# MIMXRT1062 register map
Vendor: nxp.com; File version: 1.0
CPU: CM7 r0p1, little endian, MPU, FPU, VTOR, 4 interrupt priority bits
Registers are 32-bit, read-write, reset 0x0 unless marked. A register's access mark holds for its fields unless they carry their own. Offsets are from the block's base; [hi:lo] are bit positions; {n}, {i} and the like mark numbered series; 'fields as' and 'values as' point back to an identical list.

## IOMUXC (part 3 of 4)
Base 0x401F8000; register names take the prefix IOMUXC_
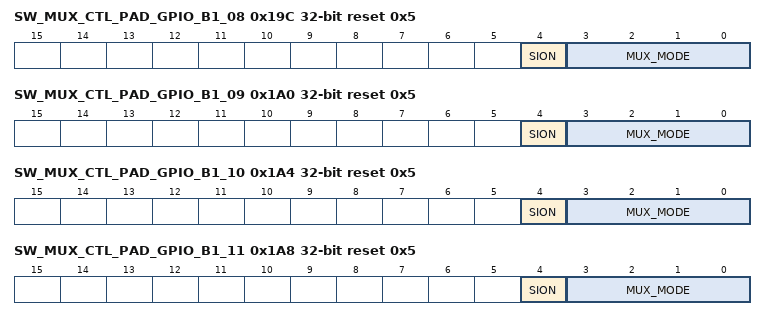
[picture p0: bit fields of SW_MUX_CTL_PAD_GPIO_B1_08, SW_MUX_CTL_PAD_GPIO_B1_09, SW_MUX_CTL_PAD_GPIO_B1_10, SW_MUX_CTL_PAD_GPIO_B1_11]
0x19C SW_MUX_CTL_PAD_GPIO_B1_08 reset 0x5 — SW_MUX_CTL_PAD_GPIO_B1_08 SW MUX Control Register
  [4] SION — Software Input On Field.
    0=DISABLED (Input Path is determined by functionality); 1=ENABLED (Force input path of pad GPIO_B1_08)
  [3:0] MUX_MODE — MUX Mode Select Field.
    0=ALT0 (Select mux mode: ALT0 mux port: LCD_DATA20 of instance: lcdif); 1=ALT1 (Select mux mode: ALT1 mux port: QTIMER1_TIMER3 of instance: qtimer1); 2=ALT2 (Select mux mode: ALT2 mux port: CSI_DATA11 of instance: csi); 3=ALT3 (Select mux mode: ALT3 mux port: ENET_TX_DATA01 of instance: enet); 4=ALT4 (Select mux mode: ALT4 mux port: FLEXIO2_FLEXIO24 of instance: flexio2); 5=ALT5 (Select mux mode: ALT5 mux port: GPIO2_IO24 of instance: gpio2); 6=ALT6 (Select mux mode: ALT6 mux port: FLEXCAN2_TX of instance: flexcan2); 8=ALT8 (Select mux mode: ALT8 mux port: GPT1_COMPARE2 of instance: gpt1); 9=ALT9 (Select mux mode: ALT9 mux port: FLEXIO3_FLEXIO24 of instance: flexio3)
0x1A0 SW_MUX_CTL_PAD_GPIO_B1_09 reset 0x5 — SW_MUX_CTL_PAD_GPIO_B1_09 SW MUX Control Register
  [4] SION — Software Input On Field.
    0=DISABLED (Input Path is determined by functionality); 1=ENABLED (Force input path of pad GPIO_B1_09)
  [3:0] MUX_MODE — MUX Mode Select Field.
    0=ALT0 (Select mux mode: ALT0 mux port: LCD_DATA21 of instance: lcdif); 1=ALT1 (Select mux mode: ALT1 mux port: QTIMER2_TIMER3 of instance: qtimer2); 2=ALT2 (Select mux mode: ALT2 mux port: CSI_DATA10 of instance: csi); 3=ALT3 (Select mux mode: ALT3 mux port: ENET_TX_EN of instance: enet); 4=ALT4 (Select mux mode: ALT4 mux port: FLEXIO2_FLEXIO25 of instance: flexio2); 5=ALT5 (Select mux mode: ALT5 mux port: GPIO2_IO25 of instance: gpio2); 6=ALT6 (Select mux mode: ALT6 mux port: FLEXCAN2_RX of instance: flexcan2); 8=ALT8 (Select mux mode: ALT8 mux port: GPT1_COMPARE3 of instance: gpt1); 9=ALT9 (Select mux mode: ALT9 mux port: FLEXIO3_FLEXIO25 of instance: flexio3)
0x1A4 SW_MUX_CTL_PAD_GPIO_B1_10 reset 0x5 — SW_MUX_CTL_PAD_GPIO_B1_10 SW MUX Control Register
  [4] SION — Software Input On Field.
    0=DISABLED (Input Path is determined by functionality); 1=ENABLED (Force input path of pad GPIO_B1_10)
  [3:0] MUX_MODE — MUX Mode Select Field.
    0=ALT0 (Select mux mode: ALT0 mux port: LCD_DATA22 of instance: lcdif); 1=ALT1 (Select mux mode: ALT1 mux port: QTIMER3_TIMER3 of instance: qtimer3); 2=ALT2 (Select mux mode: ALT2 mux port: CSI_DATA00 of instance: csi); 3=ALT3 (Select mux mode: ALT3 mux port: ENET_TX_CLK of instance: enet); 4=ALT4 (Select mux mode: ALT4 mux port: FLEXIO2_FLEXIO26 of instance: flexio2); 5=ALT5 (Select mux mode: ALT5 mux port: GPIO2_IO26 of instance: gpio2); 6=ALT6 (Select mux mode: ALT6 mux port: ENET_REF_CLK of instance: enet); 9=ALT9 (Select mux mode: ALT9 mux port: FLEXIO3_FLEXIO26 of instance: flexio3)
0x1A8 SW_MUX_CTL_PAD_GPIO_B1_11 reset 0x5 — SW_MUX_CTL_PAD_GPIO_B1_11 SW MUX Control Register
  [4] SION — Software Input On Field.
    0=DISABLED (Input Path is determined by functionality); 1=ENABLED (Force input path of pad GPIO_B1_11)
  [3:0] MUX_MODE — MUX Mode Select Field.
    0=ALT0 (Select mux mode: ALT0 mux port: LCD_DATA23 of instance: lcdif); 1=ALT1 (Select mux mode: ALT1 mux port: QTIMER4_TIMER3 of instance: qtimer4); 2=ALT2 (Select mux mode: ALT2 mux port: CSI_DATA01 of instance: csi); 3=ALT3 (Select mux mode: ALT3 mux port: ENET_RX_ER of instance: enet); 4=ALT4 (Select mux mode: ALT4 mux port: FLEXIO2_FLEXIO27 of instance: flexio2); 5=ALT5 (Select mux mode: ALT5 mux port: GPIO2_IO27 of instance: gpio2); 6=ALT6 (Select mux mode: ALT6 mux port: LPSPI4_PCS3 of instance: lpspi4); 9=ALT9 (Select mux mode: ALT9 mux port: FLEXIO3_FLEXIO27 of instance: flexio3)
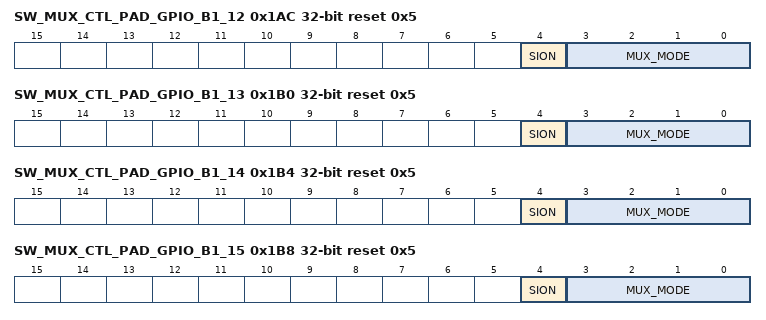
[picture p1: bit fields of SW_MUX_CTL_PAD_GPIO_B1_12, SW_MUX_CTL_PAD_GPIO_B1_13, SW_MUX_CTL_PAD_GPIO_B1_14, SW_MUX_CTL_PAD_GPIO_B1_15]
0x1AC SW_MUX_CTL_PAD_GPIO_B1_12 reset 0x5 — SW_MUX_CTL_PAD_GPIO_B1_12 SW MUX Control Register
  [4] SION — Software Input On Field.
    0=DISABLED (Input Path is determined by functionality); 1=ENABLED (Force input path of pad GPIO_B1_12)
  [3:0] MUX_MODE — MUX Mode Select Field.
    1=ALT1 (Select mux mode: ALT1 mux port: LPUART5_TX of instance: lpuart5); 2=ALT2 (Select mux mode: ALT2 mux port: CSI_PIXCLK of instance: csi); 3=ALT3 (Select mux mode: ALT3 mux port: ENET_1588_EVENT0_IN of instance: enet); 4=ALT4 (Select mux mode: ALT4 mux port: FLEXIO2_FLEXIO28 of instance: flexio2); 5=ALT5 (Select mux mode: ALT5 mux port: GPIO2_IO28 of instance: gpio2); 6=ALT6 (Select mux mode: ALT6 mux port: USDHC1_CD_B of instance: usdhc1); 9=ALT9 (Select mux mode: ALT9 mux port: FLEXIO3_FLEXIO28 of instance: flexio3)
0x1B0 SW_MUX_CTL_PAD_GPIO_B1_13 reset 0x5 — SW_MUX_CTL_PAD_GPIO_B1_13 SW MUX Control Register
  [4] SION — Software Input On Field.
    0=DISABLED (Input Path is determined by functionality); 1=ENABLED (Force input path of pad GPIO_B1_13)
  [3:0] MUX_MODE — MUX Mode Select Field.
    0=ALT0 (Select mux mode: ALT0 mux port: WDOG1_B of instance: wdog1); 1=ALT1 (Select mux mode: ALT1 mux port: LPUART5_RX of instance: lpuart5); 2=ALT2 (Select mux mode: ALT2 mux port: CSI_VSYNC of instance: csi); 3=ALT3 (Select mux mode: ALT3 mux port: ENET_1588_EVENT0_OUT of instance: enet); 4=ALT4 (Select mux mode: ALT4 mux port: FLEXIO2_FLEXIO29 of instance: flexio2); 5=ALT5 (Select mux mode: ALT5 mux port: GPIO2_IO29 of instance: gpio2); 6=ALT6 (Select mux mode: ALT6 mux port: USDHC1_WP of instance: usdhc1); 8=ALT8 (Select mux mode: ALT8 mux port: SEMC_DQS4 of instance: semc); 9=ALT9 (Select mux mode: ALT9 mux port: FLEXIO3_FLEXIO29 of instance: flexio3)
0x1B4 SW_MUX_CTL_PAD_GPIO_B1_14 reset 0x5 — SW_MUX_CTL_PAD_GPIO_B1_14 SW MUX Control Register
  [4] SION — Software Input On Field.
    0=DISABLED (Input Path is determined by functionality); 1=ENABLED (Force input path of pad GPIO_B1_14)
  [3:0] MUX_MODE — MUX Mode Select Field.
    0=ALT0 (Select mux mode: ALT0 mux port: ENET_MDC of instance: enet); 1=ALT1 (Select mux mode: ALT1 mux port: FLEXPWM4_PWMA02 of instance: flexpwm4); 2=ALT2 (Select mux mode: ALT2 mux port: CSI_HSYNC of instance: csi); 3=ALT3 (Select mux mode: ALT3 mux port: XBAR1_IN02 of instance: xbar1); 4=ALT4 (Select mux mode: ALT4 mux port: FLEXIO2_FLEXIO30 of instance: flexio2); 5=ALT5 (Select mux mode: ALT5 mux port: GPIO2_IO30 of instance: gpio2); 6=ALT6 (Select mux mode: ALT6 mux port: USDHC1_VSELECT of instance: usdhc1); 8=ALT8 (Select mux mode: ALT8 mux port: ENET2_TDATA00 of instance: enet2); 9=ALT9 (Select mux mode: ALT9 mux port: FLEXIO3_FLEXIO30 of instance: flexio3)
0x1B8 SW_MUX_CTL_PAD_GPIO_B1_15 reset 0x5 — SW_MUX_CTL_PAD_GPIO_B1_15 SW MUX Control Register
  [4] SION — Software Input On Field.
    0=DISABLED (Input Path is determined by functionality); 1=ENABLED (Force input path of pad GPIO_B1_15)
  [3:0] MUX_MODE — MUX Mode Select Field.
    0=ALT0 (Select mux mode: ALT0 mux port: ENET_MDIO of instance: enet); 1=ALT1 (Select mux mode: ALT1 mux port: FLEXPWM4_PWMA03 of instance: flexpwm4); 2=ALT2 (Select mux mode: ALT2 mux port: CSI_MCLK of instance: csi); 3=ALT3 (Select mux mode: ALT3 mux port: XBAR1_IN03 of instance: xbar1); 4=ALT4 (Select mux mode: ALT4 mux port: FLEXIO2_FLEXIO31 of instance: flexio2); 5=ALT5 (Select mux mode: ALT5 mux port: GPIO2_IO31 of instance: gpio2); 6=ALT6 (Select mux mode: ALT6 mux port: USDHC1_RESET_B of instance: usdhc1); 8=ALT8 (Select mux mode: ALT8 mux port: ENET2_TDATA01 of instance: enet2); 9=ALT9 (Select mux mode: ALT9 mux port: FLEXIO3_FLEXIO31 of instance: flexio3)
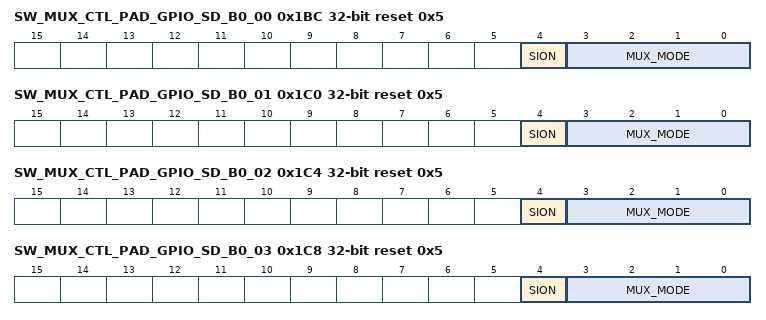
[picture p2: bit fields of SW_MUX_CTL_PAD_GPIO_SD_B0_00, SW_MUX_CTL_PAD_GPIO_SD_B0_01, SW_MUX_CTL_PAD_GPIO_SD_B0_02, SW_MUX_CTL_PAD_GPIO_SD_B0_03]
0x1BC SW_MUX_CTL_PAD_GPIO_SD_B0_00 reset 0x5 — SW_MUX_CTL_PAD_GPIO_SD_B0_00 SW MUX Control Register
  [4] SION — Software Input On Field.
    0=DISABLED (Input Path is determined by functionality); 1=ENABLED (Force input path of pad GPIO_SD_B0_00)
  [3:0] MUX_MODE — MUX Mode Select Field.
    0=ALT0 (Select mux mode: ALT0 mux port: USDHC1_CMD of instance: usdhc1); 1=ALT1 (Select mux mode: ALT1 mux port: FLEXPWM1_PWMA00 of instance: flexpwm1); 2=ALT2 (Select mux mode: ALT2 mux port: LPI2C3_SCL of instance: lpi2c3); 3=ALT3 (Select mux mode: ALT3 mux port: XBAR1_INOUT04 of instance: xbar1); 4=ALT4 (Select mux mode: ALT4 mux port: LPSPI1_SCK of instance: lpspi1); 5=ALT5 (Select mux mode: ALT5 mux port: GPIO3_IO12 of instance: gpio3); 6=ALT6 (Select mux mode: ALT6 mux port: FLEXSPIA_SS1_B of instance: flexspi); 8=ALT8 (Select mux mode: ALT8 mux port: ENET2_TX_EN of instance: enet2); 9=ALT9 (Select mux mode: ALT9 mux port: SEMC_DQS4 of instance: semc)
0x1C0 SW_MUX_CTL_PAD_GPIO_SD_B0_01 reset 0x5 — SW_MUX_CTL_PAD_GPIO_SD_B0_01 SW MUX Control Register
  [4] SION — Software Input On Field.
    0=DISABLED (Input Path is determined by functionality); 1=ENABLED (Force input path of pad GPIO_SD_B0_01)
  [3:0] MUX_MODE — MUX Mode Select Field.
    0=ALT0 (Select mux mode: ALT0 mux port: USDHC1_CLK of instance: usdhc1); 1=ALT1 (Select mux mode: ALT1 mux port: FLEXPWM1_PWMB00 of instance: flexpwm1); 2=ALT2 (Select mux mode: ALT2 mux port: LPI2C3_SDA of instance: lpi2c3); 3=ALT3 (Select mux mode: ALT3 mux port: XBAR1_INOUT05 of instance: xbar1); 4=ALT4 (Select mux mode: ALT4 mux port: LPSPI1_PCS0 of instance: lpspi1); 5=ALT5 (Select mux mode: ALT5 mux port: GPIO3_IO13 of instance: gpio3); 6=ALT6 (Select mux mode: ALT6 mux port: FLEXSPIB_SS1_B of instance: flexspi); 8=ALT8 (Select mux mode: ALT8 mux port: ENET2_TX_CLK of instance: enet2); 9=ALT9 (Select mux mode: ALT9 mux port: ENET2_REF_CLK2 of instance: enet2)
0x1C4 SW_MUX_CTL_PAD_GPIO_SD_B0_02 reset 0x5 — SW_MUX_CTL_PAD_GPIO_SD_B0_02 SW MUX Control Register
  [4] SION — Software Input On Field.
    0=DISABLED (Input Path is determined by functionality); 1=ENABLED (Force input path of pad GPIO_SD_B0_02)
  [3:0] MUX_MODE — MUX Mode Select Field.
    0=ALT0 (Select mux mode: ALT0 mux port: USDHC1_DATA0 of instance: usdhc1); 1=ALT1 (Select mux mode: ALT1 mux port: FLEXPWM1_PWMA01 of instance: flexpwm1); 2=ALT2 (Select mux mode: ALT2 mux port: LPUART8_CTS_B of instance: lpuart8); 3=ALT3 (Select mux mode: ALT3 mux port: XBAR1_INOUT06 of instance: xbar1); 4=ALT4 (Select mux mode: ALT4 mux port: LPSPI1_SDO of instance: lpspi1); 5=ALT5 (Select mux mode: ALT5 mux port: GPIO3_IO14 of instance: gpio3); 8=ALT8 (Select mux mode: ALT8 mux port: ENET2_RX_ER of instance: enet2); 9=ALT9 (Select mux mode: ALT9 mux port: SEMC_CLK5 of instance: semc)
0x1C8 SW_MUX_CTL_PAD_GPIO_SD_B0_03 reset 0x5 — SW_MUX_CTL_PAD_GPIO_SD_B0_03 SW MUX Control Register
  [4] SION — Software Input On Field.
    0=DISABLED (Input Path is determined by functionality); 1=ENABLED (Force input path of pad GPIO_SD_B0_03)
  [3:0] MUX_MODE — MUX Mode Select Field.
    0=ALT0 (Select mux mode: ALT0 mux port: USDHC1_DATA1 of instance: usdhc1); 1=ALT1 (Select mux mode: ALT1 mux port: FLEXPWM1_PWMB01 of instance: flexpwm1); 2=ALT2 (Select mux mode: ALT2 mux port: LPUART8_RTS_B of instance: lpuart8); 3=ALT3 (Select mux mode: ALT3 mux port: XBAR1_INOUT07 of instance: xbar1); 4=ALT4 (Select mux mode: ALT4 mux port: LPSPI1_SDI of instance: lpspi1); 5=ALT5 (Select mux mode: ALT5 mux port: GPIO3_IO15 of instance: gpio3); 8=ALT8 (Select mux mode: ALT8 mux port: ENET2_RDATA00 of instance: enet2); 9=ALT9 (Select mux mode: ALT9 mux port: SEMC_CLK6 of instance: semc)
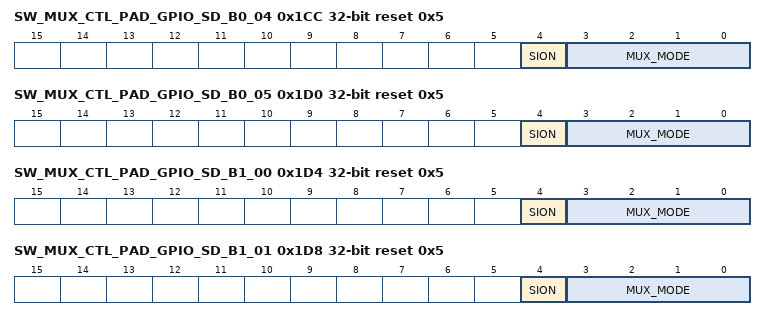
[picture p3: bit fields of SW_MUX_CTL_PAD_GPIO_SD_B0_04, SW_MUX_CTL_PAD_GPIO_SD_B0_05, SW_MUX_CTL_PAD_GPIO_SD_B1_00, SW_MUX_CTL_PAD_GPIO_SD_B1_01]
0x1CC SW_MUX_CTL_PAD_GPIO_SD_B0_04 reset 0x5 — SW_MUX_CTL_PAD_GPIO_SD_B0_04 SW MUX Control Register
  [4] SION — Software Input On Field.
    0=DISABLED (Input Path is determined by functionality); 1=ENABLED (Force input path of pad GPIO_SD_B0_04)
  [3:0] MUX_MODE — MUX Mode Select Field.
    0=ALT0 (Select mux mode: ALT0 mux port: USDHC1_DATA2 of instance: usdhc1); 1=ALT1 (Select mux mode: ALT1 mux port: FLEXPWM1_PWMA02 of instance: flexpwm1); 2=ALT2 (Select mux mode: ALT2 mux port: LPUART8_TX of instance: lpuart8); 3=ALT3 (Select mux mode: ALT3 mux port: XBAR1_INOUT08 of instance: xbar1); 4=ALT4 (Select mux mode: ALT4 mux port: FLEXSPIB_SS0_B of instance: flexspi); 5=ALT5 (Select mux mode: ALT5 mux port: GPIO3_IO16 of instance: gpio3); 6=ALT6 (Select mux mode: ALT6 mux port: CCM_CLKO1 of instance: ccm); 8=ALT8 (Select mux mode: ALT8 mux port: ENET2_RDATA01 of instance: enet2)
0x1D0 SW_MUX_CTL_PAD_GPIO_SD_B0_05 reset 0x5 — SW_MUX_CTL_PAD_GPIO_SD_B0_05 SW MUX Control Register
  [4] SION — Software Input On Field.
    0=DISABLED (Input Path is determined by functionality); 1=ENABLED (Force input path of pad GPIO_SD_B0_05)
  [3:0] MUX_MODE — MUX Mode Select Field.
    0=ALT0 (Select mux mode: ALT0 mux port: USDHC1_DATA3 of instance: usdhc1); 1=ALT1 (Select mux mode: ALT1 mux port: FLEXPWM1_PWMB02 of instance: flexpwm1); 2=ALT2 (Select mux mode: ALT2 mux port: LPUART8_RX of instance: lpuart8); 3=ALT3 (Select mux mode: ALT3 mux port: XBAR1_INOUT09 of instance: xbar1); 4=ALT4 (Select mux mode: ALT4 mux port: FLEXSPIB_DQS of instance: flexspi); 5=ALT5 (Select mux mode: ALT5 mux port: GPIO3_IO17 of instance: gpio3); 6=ALT6 (Select mux mode: ALT6 mux port: CCM_CLKO2 of instance: ccm); 8=ALT8 (Select mux mode: ALT8 mux port: ENET2_RX_EN of instance: enet2)
0x1D4 SW_MUX_CTL_PAD_GPIO_SD_B1_00 reset 0x5 — SW_MUX_CTL_PAD_GPIO_SD_B1_00 SW MUX Control Register
  [4] SION — Software Input On Field.
    0=DISABLED (Input Path is determined by functionality); 1=ENABLED (Force input path of pad GPIO_SD_B1_00)
  [3:0] MUX_MODE — MUX Mode Select Field.
    0=ALT0 (Select mux mode: ALT0 mux port: USDHC2_DATA3 of instance: usdhc2); 1=ALT1 (Select mux mode: ALT1 mux port: FLEXSPIB_DATA03 of instance: flexspi); 2=ALT2 (Select mux mode: ALT2 mux port: FLEXPWM1_PWMA03 of instance: flexpwm1); 3=ALT3 (Select mux mode: ALT3 mux port: SAI1_TX_DATA03 of instance: sai1); 4=ALT4 (Select mux mode: ALT4 mux port: LPUART4_TX of instance: lpuart4); 5=ALT5 (Select mux mode: ALT5 mux port: GPIO3_IO00 of instance: gpio3); 8=ALT8 (Select mux mode: ALT8 mux port: SAI3_RX_DATA of instance: sai3)
0x1D8 SW_MUX_CTL_PAD_GPIO_SD_B1_01 reset 0x5 — SW_MUX_CTL_PAD_GPIO_SD_B1_01 SW MUX Control Register
  [4] SION — Software Input On Field.
    0=DISABLED (Input Path is determined by functionality); 1=ENABLED (Force input path of pad GPIO_SD_B1_01)
  [3:0] MUX_MODE — MUX Mode Select Field.
    0=ALT0 (Select mux mode: ALT0 mux port: USDHC2_DATA2 of instance: usdhc2); 1=ALT1 (Select mux mode: ALT1 mux port: FLEXSPIB_DATA02 of instance: flexspi); 2=ALT2 (Select mux mode: ALT2 mux port: FLEXPWM1_PWMB03 of instance: flexpwm1); 3=ALT3 (Select mux mode: ALT3 mux port: SAI1_TX_DATA02 of instance: sai1); 4=ALT4 (Select mux mode: ALT4 mux port: LPUART4_RX of instance: lpuart4); 5=ALT5 (Select mux mode: ALT5 mux port: GPIO3_IO01 of instance: gpio3); 8=ALT8 (Select mux mode: ALT8 mux port: SAI3_TX_DATA of instance: sai3)
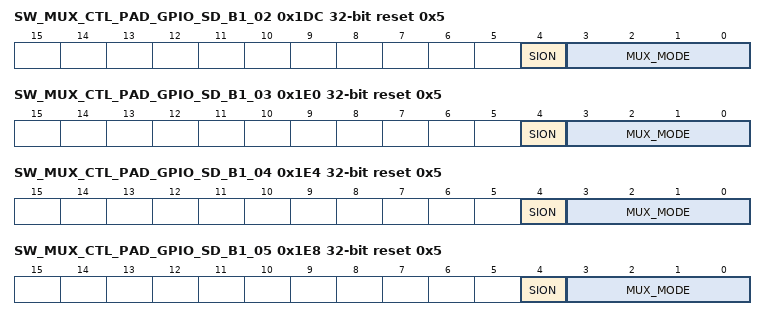
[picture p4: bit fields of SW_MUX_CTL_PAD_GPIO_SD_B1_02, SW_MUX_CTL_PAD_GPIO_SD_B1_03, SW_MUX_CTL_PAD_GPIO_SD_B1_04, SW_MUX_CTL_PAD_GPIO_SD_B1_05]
0x1DC SW_MUX_CTL_PAD_GPIO_SD_B1_02 reset 0x5 — SW_MUX_CTL_PAD_GPIO_SD_B1_02 SW MUX Control Register
  [4] SION — Software Input On Field.
    0=DISABLED (Input Path is determined by functionality); 1=ENABLED (Force input path of pad GPIO_SD_B1_02)
  [3:0] MUX_MODE — MUX Mode Select Field.
    0=ALT0 (Select mux mode: ALT0 mux port: USDHC2_DATA1 of instance: usdhc2); 1=ALT1 (Select mux mode: ALT1 mux port: FLEXSPIB_DATA01 of instance: flexspi); 2=ALT2 (Select mux mode: ALT2 mux port: FLEXPWM2_PWMA03 of instance: flexpwm2); 3=ALT3 (Select mux mode: ALT3 mux port: SAI1_TX_DATA01 of instance: sai1); 4=ALT4 (Select mux mode: ALT4 mux port: FLEXCAN1_TX of instance: flexcan1); 5=ALT5 (Select mux mode: ALT5 mux port: GPIO3_IO02 of instance: gpio3); 6=ALT6 (Select mux mode: ALT6 mux port: CCM_WAIT of instance: ccm); 8=ALT8 (Select mux mode: ALT8 mux port: SAI3_TX_SYNC of instance: sai3)
0x1E0 SW_MUX_CTL_PAD_GPIO_SD_B1_03 reset 0x5 — SW_MUX_CTL_PAD_GPIO_SD_B1_03 SW MUX Control Register
  [4] SION — Software Input On Field.
    0=DISABLED (Input Path is determined by functionality); 1=ENABLED (Force input path of pad GPIO_SD_B1_03)
  [3:0] MUX_MODE — MUX Mode Select Field.
    0=ALT0 (Select mux mode: ALT0 mux port: USDHC2_DATA0 of instance: usdhc2); 1=ALT1 (Select mux mode: ALT1 mux port: FLEXSPIB_DATA00 of instance: flexspi); 2=ALT2 (Select mux mode: ALT2 mux port: FLEXPWM2_PWMB03 of instance: flexpwm2); 3=ALT3 (Select mux mode: ALT3 mux port: SAI1_MCLK of instance: sai1); 4=ALT4 (Select mux mode: ALT4 mux port: FLEXCAN1_RX of instance: flexcan1); 5=ALT5 (Select mux mode: ALT5 mux port: GPIO3_IO03 of instance: gpio3); 6=ALT6 (Select mux mode: ALT6 mux port: CCM_PMIC_READY of instance: ccm); 8=ALT8 (Select mux mode: ALT8 mux port: SAI3_TX_BCLK of instance: sai3)
0x1E4 SW_MUX_CTL_PAD_GPIO_SD_B1_04 reset 0x5 — SW_MUX_CTL_PAD_GPIO_SD_B1_04 SW MUX Control Register
  [4] SION — Software Input On Field.
    0=DISABLED (Input Path is determined by functionality); 1=ENABLED (Force input path of pad GPIO_SD_B1_04)
  [3:0] MUX_MODE — MUX Mode Select Field.
    0=ALT0 (Select mux mode: ALT0 mux port: USDHC2_CLK of instance: usdhc2); 1=ALT1 (Select mux mode: ALT1 mux port: FLEXSPIB_SCLK of instance: flexspi); 2=ALT2 (Select mux mode: ALT2 mux port: LPI2C1_SCL of instance: lpi2c1); 3=ALT3 (Select mux mode: ALT3 mux port: SAI1_RX_SYNC of instance: sai1); 4=ALT4 (Select mux mode: ALT4 mux port: FLEXSPIA_SS1_B of instance: flexspi); 5=ALT5 (Select mux mode: ALT5 mux port: GPIO3_IO04 of instance: gpio3); 6=ALT6 (Select mux mode: ALT6 mux port: CCM_STOP of instance: ccm); 8=ALT8 (Select mux mode: ALT8 mux port: SAI3_MCLK of instance: sai3)
0x1E8 SW_MUX_CTL_PAD_GPIO_SD_B1_05 reset 0x5 — SW_MUX_CTL_PAD_GPIO_SD_B1_05 SW MUX Control Register
  [4] SION — Software Input On Field.
    0=DISABLED (Input Path is determined by functionality); 1=ENABLED (Force input path of pad GPIO_SD_B1_05)
  [3:0] MUX_MODE — MUX Mode Select Field.
    0=ALT0 (Select mux mode: ALT0 mux port: USDHC2_CMD of instance: usdhc2); 1=ALT1 (Select mux mode: ALT1 mux port: FLEXSPIA_DQS of instance: flexspi); 2=ALT2 (Select mux mode: ALT2 mux port: LPI2C1_SDA of instance: lpi2c1); 3=ALT3 (Select mux mode: ALT3 mux port: SAI1_RX_BCLK of instance: sai1); 4=ALT4 (Select mux mode: ALT4 mux port: FLEXSPIB_SS0_B of instance: flexspi); 5=ALT5 (Select mux mode: ALT5 mux port: GPIO3_IO05 of instance: gpio3); 8=ALT8 (Select mux mode: ALT8 mux port: SAI3_RX_SYNC of instance: sai3)
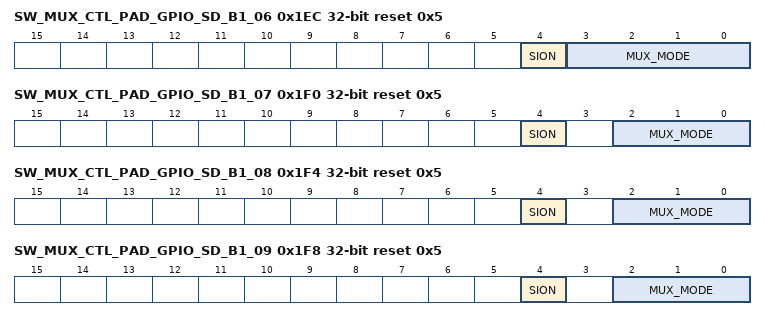
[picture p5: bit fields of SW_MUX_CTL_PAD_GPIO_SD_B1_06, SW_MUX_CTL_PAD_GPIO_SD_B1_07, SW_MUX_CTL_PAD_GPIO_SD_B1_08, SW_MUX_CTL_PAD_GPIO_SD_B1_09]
0x1EC SW_MUX_CTL_PAD_GPIO_SD_B1_06 reset 0x5 — SW_MUX_CTL_PAD_GPIO_SD_B1_06 SW MUX Control Register
  [4] SION — Software Input On Field.
    0=DISABLED (Input Path is determined by functionality); 1=ENABLED (Force input path of pad GPIO_SD_B1_06)
  [3:0] MUX_MODE — MUX Mode Select Field.
    0=ALT0 (Select mux mode: ALT0 mux port: USDHC2_RESET_B of instance: usdhc2); 1=ALT1 (Select mux mode: ALT1 mux port: FLEXSPIA_SS0_B of instance: flexspi); 2=ALT2 (Select mux mode: ALT2 mux port: LPUART7_CTS_B of instance: lpuart7); 3=ALT3 (Select mux mode: ALT3 mux port: SAI1_RX_DATA00 of instance: sai1); 4=ALT4 (Select mux mode: ALT4 mux port: LPSPI2_PCS0 of instance: lpspi2); 5=ALT5 (Select mux mode: ALT5 mux port: GPIO3_IO06 of instance: gpio3); 8=ALT8 (Select mux mode: ALT8 mux port: SAI3_RX_BCLK of instance: sai3)
0x1F0 SW_MUX_CTL_PAD_GPIO_SD_B1_07 reset 0x5 — SW_MUX_CTL_PAD_GPIO_SD_B1_07 SW MUX Control Register
  [4] SION — Software Input On Field.
    0=DISABLED (Input Path is determined by functionality); 1=ENABLED (Force input path of pad GPIO_SD_B1_07)
  [2:0] MUX_MODE — MUX Mode Select Field.
    0=ALT0 (Select mux mode: ALT0 mux port: SEMC_CSX01 of instance: semc); 1=ALT1 (Select mux mode: ALT1 mux port: FLEXSPIA_SCLK of instance: flexspi); 2=ALT2 (Select mux mode: ALT2 mux port: LPUART7_RTS_B of instance: lpuart7); 3=ALT3 (Select mux mode: ALT3 mux port: SAI1_TX_DATA00 of instance: sai1); 4=ALT4 (Select mux mode: ALT4 mux port: LPSPI2_SCK of instance: lpspi2); 5=ALT5 (Select mux mode: ALT5 mux port: GPIO3_IO07 of instance: gpio3)
0x1F4 SW_MUX_CTL_PAD_GPIO_SD_B1_08 reset 0x5 — SW_MUX_CTL_PAD_GPIO_SD_B1_08 SW MUX Control Register
  [4] SION — Software Input On Field.
    0=DISABLED (Input Path is determined by functionality); 1=ENABLED (Force input path of pad GPIO_SD_B1_08)
  [2:0] MUX_MODE — MUX Mode Select Field.
    0=ALT0 (Select mux mode: ALT0 mux port: USDHC2_DATA4 of instance: usdhc2); 1=ALT1 (Select mux mode: ALT1 mux port: FLEXSPIA_DATA00 of instance: flexspi); 2=ALT2 (Select mux mode: ALT2 mux port: LPUART7_TX of instance: lpuart7); 3=ALT3 (Select mux mode: ALT3 mux port: SAI1_TX_BCLK of instance: sai1); 4=ALT4 (Select mux mode: ALT4 mux port: LPSPI2_SD0 of instance: lpspi2); 5=ALT5 (Select mux mode: ALT5 mux port: GPIO3_IO08 of instance: gpio3); 6=ALT6 (Select mux mode: ALT6 mux port: SEMC_CSX02 of instance: semc)
0x1F8 SW_MUX_CTL_PAD_GPIO_SD_B1_09 reset 0x5 — SW_MUX_CTL_PAD_GPIO_SD_B1_09 SW MUX Control Register
  [4] SION — Software Input On Field.
    0=DISABLED (Input Path is determined by functionality); 1=ENABLED (Force input path of pad GPIO_SD_B1_09)
  [2:0] MUX_MODE — MUX Mode Select Field.
    0=ALT0 (Select mux mode: ALT0 mux port: USDHC2_DATA5 of instance: usdhc2); 1=ALT1 (Select mux mode: ALT1 mux port: FLEXSPIA_DATA01 of instance: flexspi); 2=ALT2 (Select mux mode: ALT2 mux port: LPUART7_RX of instance: lpuart7); 3=ALT3 (Select mux mode: ALT3 mux port: SAI1_TX_SYNC of instance: sai1); 4=ALT4 (Select mux mode: ALT4 mux port: LPSPI2_SDI of instance: lpspi2); 5=ALT5 (Select mux mode: ALT5 mux port: GPIO3_IO09 of instance: gpio3)
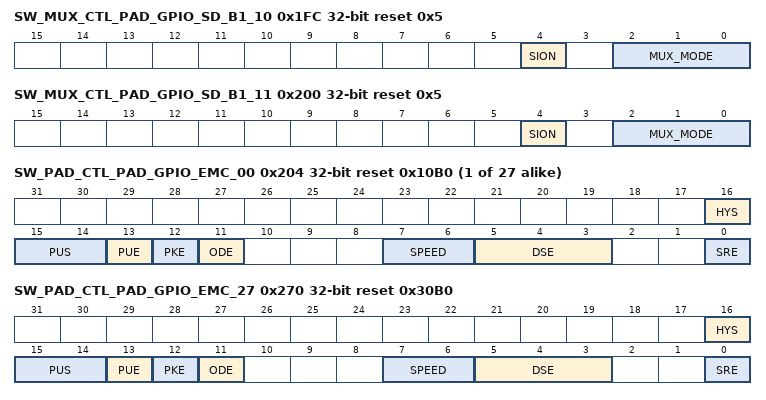
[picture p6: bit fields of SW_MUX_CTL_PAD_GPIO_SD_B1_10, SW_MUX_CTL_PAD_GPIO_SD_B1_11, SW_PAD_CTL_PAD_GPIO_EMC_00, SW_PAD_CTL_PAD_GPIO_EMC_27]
0x1FC SW_MUX_CTL_PAD_GPIO_SD_B1_10 reset 0x5 — SW_MUX_CTL_PAD_GPIO_SD_B1_10 SW MUX Control Register
  [4] SION — Software Input On Field.
    0=DISABLED (Input Path is determined by functionality); 1=ENABLED (Force input path of pad GPIO_SD_B1_10)
  [2:0] MUX_MODE — MUX Mode Select Field.
    0=ALT0 (Select mux mode: ALT0 mux port: USDHC2_DATA6 of instance: usdhc2); 1=ALT1 (Select mux mode: ALT1 mux port: FLEXSPIA_DATA02 of instance: flexspi); 2=ALT2 (Select mux mode: ALT2 mux port: LPUART2_RX of instance: lpuart2); 3=ALT3 (Select mux mode: ALT3 mux port: LPI2C2_SDA of instance: lpi2c2); 4=ALT4 (Select mux mode: ALT4 mux port: LPSPI2_PCS2 of instance: lpspi2); 5=ALT5 (Select mux mode: ALT5 mux port: GPIO3_IO10 of instance: gpio3)
0x200 SW_MUX_CTL_PAD_GPIO_SD_B1_11 reset 0x5 — SW_MUX_CTL_PAD_GPIO_SD_B1_11 SW MUX Control Register
  [4] SION — Software Input On Field.
    0=DISABLED (Input Path is determined by functionality); 1=ENABLED (Force input path of pad GPIO_SD_B1_11)
  [2:0] MUX_MODE — MUX Mode Select Field.
    0=ALT0 (Select mux mode: ALT0 mux port: USDHC2_DATA7 of instance: usdhc2); 1=ALT1 (Select mux mode: ALT1 mux port: FLEXSPIA_DATA03 of instance: flexspi); 2=ALT2 (Select mux mode: ALT2 mux port: LPUART2_TX of instance: lpuart2); 3=ALT3 (Select mux mode: ALT3 mux port: LPI2C2_SCL of instance: lpi2c2); 4=ALT4 (Select mux mode: ALT4 mux port: LPSPI2_PCS3 of instance: lpspi2); 5=ALT5 (Select mux mode: ALT5 mux port: GPIO3_IO11 of instance: gpio3)
{0x204+4i} SW_PAD_CTL_PAD_GPIO_EMC_{i:02} reset 0x10B0 (i=0..26) — SW_PAD_CTL_PAD_GPIO_EMC_{i:02} SW PAD Control Register
  [16] HYS — Hyst. Enable Field
    0=HYS_0_Hysteresis_Disabled (Hysteresis Disabled); 1=HYS_1_Hysteresis_Enabled (Hysteresis Enabled)
  [15:14] PUS — Pull Up / Down Config. Field
    0=PUS_0_100K_Ohm_Pull_Down (100K Ohm Pull Down); 1=PUS_1_47K_Ohm_Pull_Up (47K Ohm Pull Up); 2=PUS_2_100K_Ohm_Pull_Up (100K Ohm Pull Up); 3=PUS_3_22K_Ohm_Pull_Up (22K Ohm Pull Up)
  [13] PUE — Pull / Keep Select Field
    0=PUE_0_Keeper (Keeper); 1=PUE_1_Pull (Pull)
  [12] PKE — Pull / Keep Enable Field
    0=PKE_0_Pull_Keeper_Disabled (Pull/Keeper Disabled); 1=PKE_1_Pull_Keeper_Enabled (Pull/Keeper Enabled)
  [11] ODE — Open Drain Enable Field
    0=ODE_0_Open_Drain_Disabled (Open Drain Disabled); 1=ODE_1_Open_Drain_Enabled (Open Drain Enabled)
  [7:6] SPEED
    0=SPEED_0_low_50MHz (low(50MHz)); 1=SPEED_1_medium_100MHz (medium(100MHz)); 2=SPEED_2_fast_150MHz (fast(150MHz)); 3=SPEED_3_max_200MHz (max(200MHz))
  [5:3] DSE — Drive Strength Field
    0=DSE_0_output_driver_disabled (output driver disabled;); 1=DSE_1_R0_150_Ohm_3_3V_260_Ohm_1_8V (R0(150 Ohm @ 3.3V, 260 Ohm@1.8V)); {v}=DSE_{v}_R0_{v} (R0/{v}) (v=2..7)
  [0] SRE — Slew Rate Field
    0=SRE_0_Slow_Slew_Rate (Slow Slew Rate); 1=SRE_1_Fast_Slew_Rate (Fast Slew Rate)
0x270 SW_PAD_CTL_PAD_GPIO_EMC_27 reset 0x30B0 — SW_PAD_CTL_PAD_GPIO_EMC_27 SW PAD Control Register
  fields as SW_PAD_CTL_PAD_GPIO_EMC_00
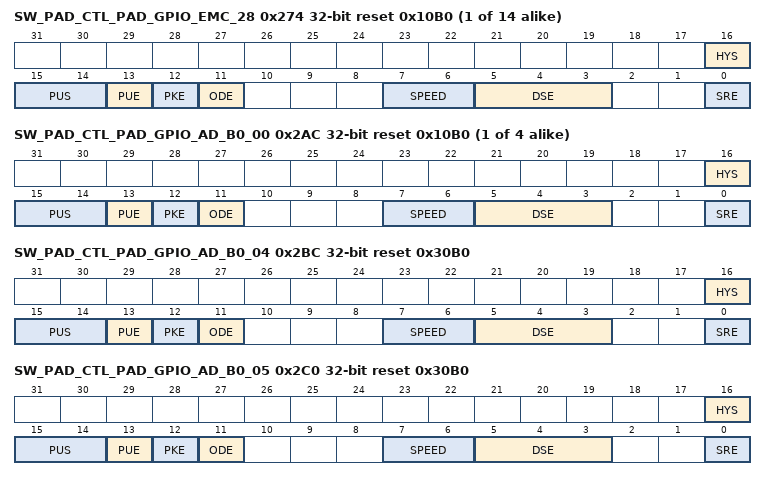
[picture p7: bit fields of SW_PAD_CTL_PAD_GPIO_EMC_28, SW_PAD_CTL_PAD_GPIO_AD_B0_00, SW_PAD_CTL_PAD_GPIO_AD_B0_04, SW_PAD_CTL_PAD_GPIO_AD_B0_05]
{0x204+4i} SW_PAD_CTL_PAD_GPIO_EMC_{i} reset 0x10B0 (i=28..41) — SW_PAD_CTL_PAD_GPIO_EMC_{i} SW PAD Control Register
  fields as SW_PAD_CTL_PAD_GPIO_EMC_00
{0x2AC+4i} SW_PAD_CTL_PAD_GPIO_AD_B0_{i:02} reset 0x10B0 (i=0..3) — SW_PAD_CTL_PAD_GPIO_AD_B0_{i:02} SW PAD Control Register
  fields as SW_PAD_CTL_PAD_GPIO_EMC_00
0x2BC SW_PAD_CTL_PAD_GPIO_AD_B0_04 reset 0x30B0 — SW_PAD_CTL_PAD_GPIO_AD_B0_04 SW PAD Control Register
  fields as SW_PAD_CTL_PAD_GPIO_EMC_00
0x2C0 SW_PAD_CTL_PAD_GPIO_AD_B0_05 reset 0x30B0 — SW_PAD_CTL_PAD_GPIO_AD_B0_05 SW PAD Control Register
  fields as SW_PAD_CTL_PAD_GPIO_EMC_00
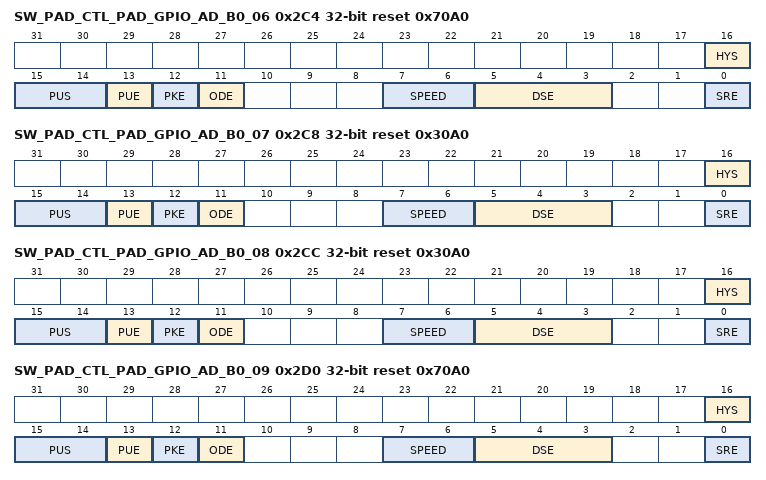
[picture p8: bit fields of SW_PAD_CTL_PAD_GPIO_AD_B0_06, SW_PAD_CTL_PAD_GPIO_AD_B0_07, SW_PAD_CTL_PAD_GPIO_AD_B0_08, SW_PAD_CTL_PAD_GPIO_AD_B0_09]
0x2C4 SW_PAD_CTL_PAD_GPIO_AD_B0_06 reset 0x70A0 — SW_PAD_CTL_PAD_GPIO_AD_B0_06 SW PAD Control Register
  fields as SW_PAD_CTL_PAD_GPIO_EMC_00
0x2C8 SW_PAD_CTL_PAD_GPIO_AD_B0_07 reset 0x30A0 — SW_PAD_CTL_PAD_GPIO_AD_B0_07 SW PAD Control Register
  fields as SW_PAD_CTL_PAD_GPIO_EMC_00
0x2CC SW_PAD_CTL_PAD_GPIO_AD_B0_08 reset 0x30A0 — SW_PAD_CTL_PAD_GPIO_AD_B0_08 SW PAD Control Register
  fields as SW_PAD_CTL_PAD_GPIO_EMC_00
0x2D0 SW_PAD_CTL_PAD_GPIO_AD_B0_09 reset 0x70A0 — SW_PAD_CTL_PAD_GPIO_AD_B0_09 SW PAD Control Register
  fields as SW_PAD_CTL_PAD_GPIO_EMC_00
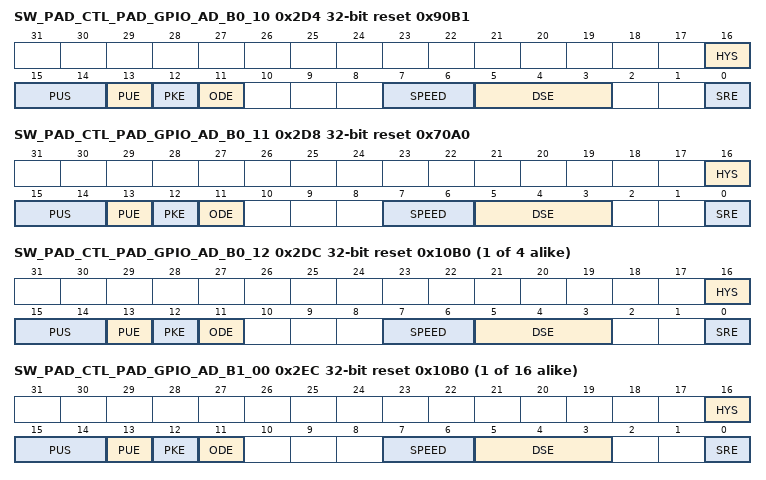
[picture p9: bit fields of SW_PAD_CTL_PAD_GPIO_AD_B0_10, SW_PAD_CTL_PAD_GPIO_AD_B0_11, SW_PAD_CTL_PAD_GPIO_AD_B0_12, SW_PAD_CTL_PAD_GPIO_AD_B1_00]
0x2D4 SW_PAD_CTL_PAD_GPIO_AD_B0_10 reset 0x90B1 — SW_PAD_CTL_PAD_GPIO_AD_B0_10 SW PAD Control Register
  fields as SW_PAD_CTL_PAD_GPIO_EMC_00
0x2D8 SW_PAD_CTL_PAD_GPIO_AD_B0_11 reset 0x70A0 — SW_PAD_CTL_PAD_GPIO_AD_B0_11 SW PAD Control Register
  fields as SW_PAD_CTL_PAD_GPIO_EMC_00
{0x2AC+4i} SW_PAD_CTL_PAD_GPIO_AD_B0_{i} reset 0x10B0 (i=12..15) — SW_PAD_CTL_PAD_GPIO_AD_B0_{i} SW PAD Control Register
  fields as SW_PAD_CTL_PAD_GPIO_EMC_00
{0x2EC+4i} SW_PAD_CTL_PAD_GPIO_AD_B1_{i:02} reset 0x10B0 (i=0..15) — SW_PAD_CTL_PAD_GPIO_AD_B1_{i:02} SW PAD Control Register
  fields as SW_PAD_CTL_PAD_GPIO_EMC_00
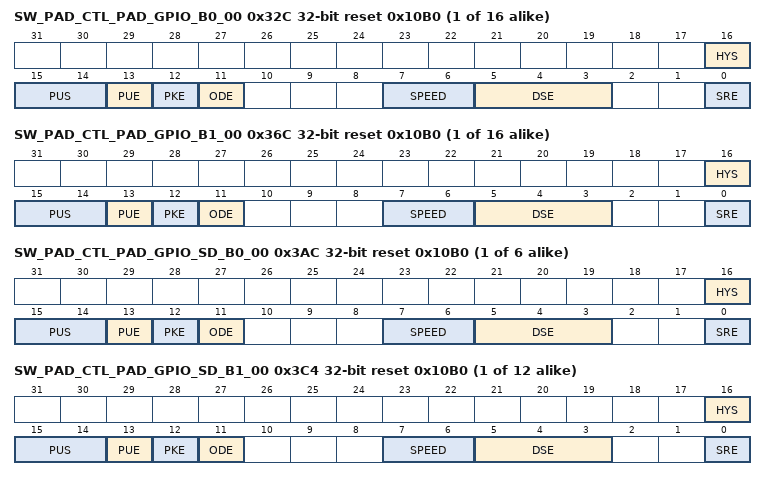
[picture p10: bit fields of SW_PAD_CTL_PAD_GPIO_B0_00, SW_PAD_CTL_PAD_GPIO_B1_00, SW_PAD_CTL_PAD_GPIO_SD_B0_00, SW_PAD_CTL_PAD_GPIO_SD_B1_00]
{0x32C+4i} SW_PAD_CTL_PAD_GPIO_B0_{i:02} reset 0x10B0 (i=0..15) — SW_PAD_CTL_PAD_GPIO_B0_{i:02} SW PAD Control Register
  fields as SW_PAD_CTL_PAD_GPIO_EMC_00
{0x36C+4i} SW_PAD_CTL_PAD_GPIO_B1_{i:02} reset 0x10B0 (i=0..15) — SW_PAD_CTL_PAD_GPIO_B1_{i:02} SW PAD Control Register
  fields as SW_PAD_CTL_PAD_GPIO_EMC_00
{0x3AC+4i} SW_PAD_CTL_PAD_GPIO_SD_B0_{i:02} reset 0x10B0 (i=0..5) — SW_PAD_CTL_PAD_GPIO_SD_B0_{i:02} SW PAD Control Register
  fields as SW_PAD_CTL_PAD_GPIO_EMC_00
{0x3C4+4i} SW_PAD_CTL_PAD_GPIO_SD_B1_{i:02} reset 0x10B0 (i=0..11) — SW_PAD_CTL_PAD_GPIO_SD_B1_{i:02} SW PAD Control Register
  fields as SW_PAD_CTL_PAD_GPIO_EMC_00
0x3F4 ANATOP_USB_OTG1_ID_SELECT_INPUT — ANATOP_USB_OTG1_ID_SELECT_INPUT DAISY Register
  [0] DAISY — Selecting Pads Involved in Daisy Chain.
    0=GPIO_AD_B0_01_ALT3 (Selecting Pad: GPIO_AD_B0_01 for Mode: ALT3); 1=GPIO_AD_B1_02_ALT0 (Selecting Pad: GPIO_AD_B1_02 for Mode: ALT0)
0x3F8 ANATOP_USB_OTG2_ID_SELECT_INPUT — ANATOP_USB_OTG2_ID_SELECT_INPUT DAISY Register
  [0] DAISY — Selecting Pads Involved in Daisy Chain.
    0=GPIO_AD_B0_00_ALT3 (Selecting Pad: GPIO_AD_B0_00 for Mode: ALT3); 1=GPIO_AD_B1_00_ALT0 (Selecting Pad: GPIO_AD_B1_00 for Mode: ALT0)
0x3FC CCM_PMIC_READY_SELECT_INPUT — CCM_PMIC_READY_SELECT_INPUT DAISY Register
  [2:0] DAISY — Selecting Pads Involved in Daisy Chain.
    0=GPIO_SD_B1_03_ALT6 (Selecting Pad: GPIO_SD_B1_03 for Mode: ALT6); 1=GPIO_AD_B0_12_ALT1 (Selecting Pad: GPIO_AD_B0_12 for Mode: ALT1); 2=GPIO_AD_B1_01_ALT4 (Selecting Pad: GPIO_AD_B1_01 for Mode: ALT4); 3=GPIO_AD_B1_08_ALT3 (Selecting Pad: GPIO_AD_B1_08 for Mode: ALT3); 4=GPIO_EMC_32_ALT3 (Selecting Pad: GPIO_EMC_32 for Mode: ALT3)
0x400 CSI_DATA02_SELECT_INPUT — CSI_DATA02_SELECT_INPUT DAISY Register
  [0] DAISY — Selecting Pads Involved in Daisy Chain.
    0=GPIO_AD_B1_15_ALT4 (Selecting Pad: GPIO_AD_B1_15 for Mode: ALT4); 1=GPIO_AD_B0_11_ALT4 (Selecting Pad: GPIO_AD_B0_11 for Mode: ALT4)
0x404 CSI_DATA03_SELECT_INPUT — CSI_DATA03_SELECT_INPUT DAISY Register
  [0] DAISY — Selecting Pads Involved in Daisy Chain.
    0=GPIO_AD_B1_14_ALT4 (Selecting Pad: GPIO_AD_B1_14 for Mode: ALT4); 1=GPIO_AD_B0_10_ALT4 (Selecting Pad: GPIO_AD_B0_10 for Mode: ALT4)
0x408 CSI_DATA04_SELECT_INPUT — CSI_DATA04_SELECT_INPUT DAISY Register
  [0] DAISY — Selecting Pads Involved in Daisy Chain.
    0=GPIO_AD_B1_13_ALT4 (Selecting Pad: GPIO_AD_B1_13 for Mode: ALT4); 1=GPIO_AD_B0_09_ALT4 (Selecting Pad: GPIO_AD_B0_09 for Mode: ALT4)
0x40C CSI_DATA05_SELECT_INPUT — CSI_DATA05_SELECT_INPUT DAISY Register
  [0] DAISY — Selecting Pads Involved in Daisy Chain.
    0=GPIO_AD_B1_12_ALT4 (Selecting Pad: GPIO_AD_B1_12 for Mode: ALT4); 1=GPIO_AD_B0_08_ALT4 (Selecting Pad: GPIO_AD_B0_08 for Mode: ALT4)
0x410 CSI_DATA06_SELECT_INPUT — CSI_DATA06_SELECT_INPUT DAISY Register
  [0] DAISY — Selecting Pads Involved in Daisy Chain.
    0=GPIO_AD_B1_11_ALT4 (Selecting Pad: GPIO_AD_B1_11 for Mode: ALT4); 1=GPIO_AD_B0_07_ALT4 (Selecting Pad: GPIO_AD_B0_07 for Mode: ALT4)
0x414 CSI_DATA07_SELECT_INPUT — CSI_DATA07_SELECT_INPUT DAISY Register
  [0] DAISY — Selecting Pads Involved in Daisy Chain.
    0=GPIO_AD_B1_10_ALT4 (Selecting Pad: GPIO_AD_B1_10 for Mode: ALT4); 1=GPIO_AD_B0_06_ALT4 (Selecting Pad: GPIO_AD_B0_06 for Mode: ALT4)
0x418 CSI_DATA08_SELECT_INPUT — CSI_DATA08_SELECT_INPUT DAISY Register
  [0] DAISY — Selecting Pads Involved in Daisy Chain.
    0=GPIO_AD_B1_09_ALT4 (Selecting Pad: GPIO_AD_B1_09 for Mode: ALT4); 1=GPIO_AD_B0_05_ALT4 (Selecting Pad: GPIO_AD_B0_05 for Mode: ALT4)
0x41C CSI_DATA09_SELECT_INPUT — CSI_DATA09_SELECT_INPUT DAISY Register
  [0] DAISY — Selecting Pads Involved in Daisy Chain.
    0=GPIO_AD_B1_08_ALT4 (Selecting Pad: GPIO_AD_B1_08 for Mode: ALT4); 1=GPIO_AD_B0_04_ALT4 (Selecting Pad: GPIO_AD_B0_04 for Mode: ALT4)
0x420 CSI_HSYNC_SELECT_INPUT — CSI_HSYNC_SELECT_INPUT DAISY Register
  [1:0] DAISY — Selecting Pads Involved in Daisy Chain.
    0=GPIO_AD_B0_15_ALT4 (Selecting Pad: GPIO_AD_B0_15 for Mode: ALT4); 1=GPIO_AD_B1_07_ALT4 (Selecting Pad: GPIO_AD_B1_07 for Mode: ALT4); 2=GPIO_B1_14_ALT2 (Selecting Pad: GPIO_B1_14 for Mode: ALT2)
0x424 CSI_PIXCLK_SELECT_INPUT — CSI_PIXCLK_SELECT_INPUT DAISY Register
  [0] DAISY — Selecting Pads Involved in Daisy Chain.
    0=GPIO_AD_B1_04_ALT4 (Selecting Pad: GPIO_AD_B1_04 for Mode: ALT4); 1=GPIO_B1_12_ALT2 (Selecting Pad: GPIO_B1_12 for Mode: ALT2)
0x428 CSI_VSYNC_SELECT_INPUT — CSI_VSYNC_SELECT_INPUT DAISY Register
  [1:0] DAISY — Selecting Pads Involved in Daisy Chain.
    0=GPIO_AD_B0_14_ALT4 (Selecting Pad: GPIO_AD_B0_14 for Mode: ALT4); 1=GPIO_AD_B1_06_ALT4 (Selecting Pad: GPIO_AD_B1_06 for Mode: ALT4); 2=GPIO_B1_13_ALT2 (Selecting Pad: GPIO_B1_13 for Mode: ALT2)
0x42C ENET_IPG_CLK_RMII_SELECT_INPUT — ENET_IPG_CLK_RMII_SELECT_INPUT DAISY Register
  [0] DAISY — Selecting Pads Involved in Daisy Chain.
    0=GPIO_EMC_25_ALT4 (Selecting Pad: GPIO_EMC_25 for Mode: ALT4); 1=GPIO_B1_10_ALT6 (Selecting Pad: GPIO_B1_10 for Mode: ALT6)
0x430 ENET_MDIO_SELECT_INPUT — ENET_MDIO_SELECT_INPUT DAISY Register
  [1:0] DAISY — Selecting Pads Involved in Daisy Chain.
    0=GPIO_AD_B1_05_ALT1 (Selecting Pad: GPIO_AD_B1_05 for Mode: ALT1); 1=GPIO_EMC_41_ALT4 (Selecting Pad: GPIO_EMC_41 for Mode: ALT4); 2=GPIO_B1_15_ALT0 (Selecting Pad: GPIO_B1_15 for Mode: ALT0)
0x434 ENET0_RXDATA_SELECT_INPUT — ENET0_RXDATA_SELECT_INPUT DAISY Register
  [0] DAISY — Selecting Pads Involved in Daisy Chain.
    0=GPIO_EMC_20_ALT3 (Selecting Pad: GPIO_EMC_20 for Mode: ALT3); 1=GPIO_B1_04_ALT3 (Selecting Pad: GPIO_B1_04 for Mode: ALT3)
0x438 ENET1_RXDATA_SELECT_INPUT — ENET1_RXDATA_SELECT_INPUT DAISY Register
  [0] DAISY — Selecting Pads Involved in Daisy Chain.
    0=GPIO_EMC_19_ALT3 (Selecting Pad: GPIO_EMC_19 for Mode: ALT3); 1=GPIO_B1_05_ALT3 (Selecting Pad: GPIO_B1_05 for Mode: ALT3)
0x43C ENET_RXEN_SELECT_INPUT — ENET_RXEN_SELECT_INPUT DAISY Register
  [0] DAISY — Selecting Pads Involved in Daisy Chain.
    0=GPIO_EMC_23_ALT3 (Selecting Pad: GPIO_EMC_23 for Mode: ALT3); 1=GPIO_B1_06_ALT3 (Selecting Pad: GPIO_B1_06 for Mode: ALT3)
0x440 ENET_RXERR_SELECT_INPUT — ENET_RXERR_SELECT_INPUT DAISY Register
  [0] DAISY — Selecting Pads Involved in Daisy Chain.
    0=GPIO_EMC_26_ALT3 (Selecting Pad: GPIO_EMC_26 for Mode: ALT3); 1=GPIO_B1_11_ALT3 (Selecting Pad: GPIO_B1_11 for Mode: ALT3)
0x444 ENET0_TIMER_SELECT_INPUT — ENET0_TIMER_SELECT_INPUT DAISY Register
  [1:0] DAISY — Selecting Pads Involved in Daisy Chain.
    0=GPIO_AD_B0_15_ALT3 (Selecting Pad: GPIO_AD_B0_15 for Mode: ALT3); 1=GPIO_AD_B0_11_ALT7 (Selecting Pad: GPIO_AD_B0_11 for Mode: ALT7); 2=GPIO_B1_12_ALT3 (Selecting Pad: GPIO_B1_12 for Mode: ALT3)
0x448 ENET_TXCLK_SELECT_INPUT — ENET_TXCLK_SELECT_INPUT DAISY Register
  [0] DAISY — Selecting Pads Involved in Daisy Chain.
    0=GPIO_EMC_25_ALT3 (Selecting Pad: GPIO_EMC_25 for Mode: ALT3); 1=GPIO_B1_10_ALT3 (Selecting Pad: GPIO_B1_10 for Mode: ALT3)
0x44C FLEXCAN1_RX_SELECT_INPUT — FLEXCAN1_RX_SELECT_INPUT DAISY Register
  [1:0] DAISY — Selecting Pads Involved in Daisy Chain.
    0=GPIO_SD_B1_03_ALT4 (Selecting Pad: GPIO_SD_B1_03 for Mode: ALT4); 1=GPIO_EMC_18_ALT3 (Selecting Pad: GPIO_EMC_18 for Mode: ALT3); 2=GPIO_AD_B1_09_ALT2 (Selecting Pad: GPIO_AD_B1_09 for Mode: ALT2); 3=GPIO_B0_03_ALT2 (Selecting Pad: GPIO_B0_03 for Mode: ALT2)
0x450 FLEXCAN2_RX_SELECT_INPUT — FLEXCAN2_RX_SELECT_INPUT DAISY Register
  [1:0] DAISY — Selecting Pads Involved in Daisy Chain.
    0=GPIO_EMC_10_ALT3 (Selecting Pad: GPIO_EMC_10 for Mode: ALT3); 1=GPIO_AD_B0_03_ALT0 (Selecting Pad: GPIO_AD_B0_03 for Mode: ALT0); 2=GPIO_AD_B0_15_ALT6 (Selecting Pad: GPIO_AD_B0_15 for Mode: ALT6); 3=GPIO_B1_09_ALT6 (Selecting Pad: GPIO_B1_09 for Mode: ALT6)
0x454 FLEXPWM1_PWMA3_SELECT_INPUT — FLEXPWM1_PWMA3_SELECT_INPUT DAISY Register
  [2:0] DAISY — Selecting Pads Involved in Daisy Chain.
    0=GPIO_SD_B1_00_ALT2 (Selecting Pad: GPIO_SD_B1_00 for Mode: ALT2); 1=GPIO_EMC_12_ALT4 (Selecting Pad: GPIO_EMC_12 for Mode: ALT4); 2=GPIO_EMC_38_ALT1 (Selecting Pad: GPIO_EMC_38 for Mode: ALT1); 3=GPIO_AD_B0_10_ALT1 (Selecting Pad: GPIO_AD_B0_10 for Mode: ALT1); 4=GPIO_B1_00_ALT6 (Selecting Pad: GPIO_B1_00 for Mode: ALT6)
{0x458+4i} FLEXPWM1_PWMA{i}_SELECT_INPUT (i=0..2) — FLEXPWM1_PWMA{i}_SELECT_INPUT DAISY Register
  [0] DAISY — Selecting Pads Involved in Daisy Chain.
    0=GPIO_EMC_{2i+23}_ALT1 (Selecting Pad: GPIO_EMC_{2i+23} for Mode: ALT1); 1=GPIO_SD_B0_{2i:02}_ALT1 (Selecting Pad: GPIO_SD_B0_{2i:02} for Mode: ALT1)
0x464 FLEXPWM1_PWMB3_SELECT_INPUT — FLEXPWM1_PWMB3_SELECT_INPUT DAISY Register
  [2:0] DAISY — Selecting Pads Involved in Daisy Chain.
    0=GPIO_SD_B1_01_ALT2 (Selecting Pad: GPIO_SD_B1_01 for Mode: ALT2); 1=GPIO_EMC_13_ALT4 (Selecting Pad: GPIO_EMC_13 for Mode: ALT4); 2=GPIO_EMC_39_ALT1 (Selecting Pad: GPIO_EMC_39 for Mode: ALT1); 3=GPIO_AD_B0_11_ALT1 (Selecting Pad: GPIO_AD_B0_11 for Mode: ALT1); 4=GPIO_B1_01_ALT6 (Selecting Pad: GPIO_B1_01 for Mode: ALT6)
{0x468+4i} FLEXPWM1_PWMB{i}_SELECT_INPUT (i=0..2) — FLEXPWM1_PWMB{i}_SELECT_INPUT DAISY Register
  [0] DAISY — Selecting Pads Involved in Daisy Chain.
    0=GPIO_EMC_{2i+24}_ALT1 (Selecting Pad: GPIO_EMC_{2i+24} for Mode: ALT1); 1=GPIO_SD_B0_{2i+1:02}_ALT1 (Selecting Pad: GPIO_SD_B0_{2i+1:02} for Mode: ALT1)
0x474 FLEXPWM2_PWMA3_SELECT_INPUT — FLEXPWM2_PWMA3_SELECT_INPUT DAISY Register
  [2:0] DAISY — Selecting Pads Involved in Daisy Chain.
    0=GPIO_SD_B1_02_ALT2 (Selecting Pad: GPIO_SD_B1_02 for Mode: ALT2); 1=GPIO_EMC_19_ALT1 (Selecting Pad: GPIO_EMC_19 for Mode: ALT1); 2=GPIO_AD_B0_00_ALT0 (Selecting Pad: GPIO_AD_B0_00 for Mode: ALT0); 3=GPIO_AD_B0_09_ALT1 (Selecting Pad: GPIO_AD_B0_09 for Mode: ALT1); 4=GPIO_B1_02_ALT6 (Selecting Pad: GPIO_B1_02 for Mode: ALT6)
{0x478+4i} FLEXPWM2_PWMA{i}_SELECT_INPUT (i=0..2) — FLEXPWM2_PWMA{i}_SELECT_INPUT DAISY Register
  [0] DAISY — Selecting Pads Involved in Daisy Chain.
    0=GPIO_EMC_{2i+6:02}_ALT1 (Selecting Pad: GPIO_EMC_{2i+6:02} for Mode: ALT1); 1=GPIO_B0_{2i+6:02}_ALT2 (Selecting Pad: GPIO_B0_{2i+6:02} for Mode: ALT2)
0x484 FLEXPWM2_PWMB3_SELECT_INPUT — FLEXPWM2_PWMB3_SELECT_INPUT DAISY Register
  [1:0] DAISY — Selecting Pads Involved in Daisy Chain.
    0=GPIO_SD_B1_03_ALT2 (Selecting Pad: GPIO_SD_B1_03 for Mode: ALT2); 1=GPIO_EMC_20_ALT1 (Selecting Pad: GPIO_EMC_20 for Mode: ALT1); 2=GPIO_AD_B0_01_ALT0 (Selecting Pad: GPIO_AD_B0_01 for Mode: ALT0); 3=GPIO_B1_03_ALT6 (Selecting Pad: GPIO_B1_03 for Mode: ALT6)
{0x488+4i} FLEXPWM2_PWMB{i}_SELECT_INPUT (i=0..2) — FLEXPWM2_PWMB{i}_SELECT_INPUT DAISY Register
  [0] DAISY — Selecting Pads Involved in Daisy Chain.
    0=GPIO_EMC_{2i+7:02}_ALT1 (Selecting Pad: GPIO_EMC_{2i+7:02} for Mode: ALT1); 1=GPIO_B0_{2i+7:02}_ALT2 (Selecting Pad: GPIO_B0_{2i+7:02} for Mode: ALT2)
0x494 FLEXPWM4_PWMA0_SELECT_INPUT — FLEXPWM4_PWMA0_SELECT_INPUT DAISY Register
  [0] DAISY — Selecting Pads Involved in Daisy Chain.
    0=GPIO_EMC_00_ALT1 (Selecting Pad: GPIO_EMC_00 for Mode: ALT1); 1=GPIO_AD_B1_08_ALT1 (Selecting Pad: GPIO_AD_B1_08 for Mode: ALT1)
0x498 FLEXPWM4_PWMA1_SELECT_INPUT — FLEXPWM4_PWMA1_SELECT_INPUT DAISY Register
  [0] DAISY — Selecting Pads Involved in Daisy Chain.
    0=GPIO_EMC_02_ALT1 (Selecting Pad: GPIO_EMC_02 for Mode: ALT1); 1=GPIO_AD_B1_09_ALT1 (Selecting Pad: GPIO_AD_B1_09 for Mode: ALT1)
0x49C FLEXPWM4_PWMA2_SELECT_INPUT — FLEXPWM4_PWMA2_SELECT_INPUT DAISY Register
  [0] DAISY — Selecting Pads Involved in Daisy Chain.
    0=GPIO_EMC_04_ALT1 (Selecting Pad: GPIO_EMC_04 for Mode: ALT1); 1=GPIO_B1_14_ALT1 (Selecting Pad: GPIO_B1_14 for Mode: ALT1)
0x4A0 FLEXPWM4_PWMA3_SELECT_INPUT — FLEXPWM4_PWMA3_SELECT_INPUT DAISY Register
  [0] DAISY — Selecting Pads Involved in Daisy Chain.
    0=GPIO_EMC_17_ALT1 (Selecting Pad: GPIO_EMC_17 for Mode: ALT1); 1=GPIO_B1_15_ALT1 (Selecting Pad: GPIO_B1_15 for Mode: ALT1)
0x4A4 FLEXSPIA_DQS_SELECT_INPUT — FLEXSPIA_DQS_SELECT_INPUT DAISY Register
  [0] DAISY — Selecting Pads Involved in Daisy Chain.
    0=GPIO_SD_B1_05_ALT1 (Selecting Pad: GPIO_SD_B1_05 for Mode: ALT1); 1=GPIO_AD_B1_09_ALT0 (Selecting Pad: GPIO_AD_B1_09 for Mode: ALT0)
0x4A8 FLEXSPIA_DATA0_SELECT_INPUT — FLEXSPIA_DATA0_SELECT_INPUT DAISY Register
  [0] DAISY — Selecting Pads Involved in Daisy Chain.
    0=GPIO_SD_B1_08_ALT1 (Selecting Pad: GPIO_SD_B1_08 for Mode: ALT1); 1=GPIO_AD_B1_13_ALT0 (Selecting Pad: GPIO_AD_B1_13 for Mode: ALT0)
0x4AC FLEXSPIA_DATA1_SELECT_INPUT — FLEXSPIA_DATA1_SELECT_INPUT DAISY Register
  [0] DAISY — Selecting Pads Involved in Daisy Chain.
    0=GPIO_SD_B1_09_ALT1 (Selecting Pad: GPIO_SD_B1_09 for Mode: ALT1); 1=GPIO_AD_B1_12_ALT0 (Selecting Pad: GPIO_AD_B1_12 for Mode: ALT0)
0x4B0 FLEXSPIA_DATA2_SELECT_INPUT — FLEXSPIA_DATA2_SELECT_INPUT DAISY Register
  [0] DAISY — Selecting Pads Involved in Daisy Chain.
    0=GPIO_SD_B1_10_ALT1 (Selecting Pad: GPIO_SD_B1_10 for Mode: ALT1); 1=GPIO_AD_B1_11_ALT0 (Selecting Pad: GPIO_AD_B1_11 for Mode: ALT0)
0x4B4 FLEXSPIA_DATA3_SELECT_INPUT — FLEXSPIA_DATA3_SELECT_INPUT DAISY Register
  [0] DAISY — Selecting Pads Involved in Daisy Chain.
    0=GPIO_SD_B1_11_ALT1 (Selecting Pad: GPIO_SD_B1_11 for Mode: ALT1); 1=GPIO_AD_B1_10_ALT0 (Selecting Pad: GPIO_AD_B1_10 for Mode: ALT0)
0x4B8 FLEXSPIB_DATA0_SELECT_INPUT — FLEXSPIB_DATA0_SELECT_INPUT DAISY Register
  [0] DAISY — Selecting Pads Involved in Daisy Chain.
    0=GPIO_SD_B1_03_ALT1 (Selecting Pad: GPIO_SD_B1_03 for Mode: ALT1); 1=GPIO_AD_B1_07_ALT0 (Selecting Pad: GPIO_AD_B1_07 for Mode: ALT0)
0x4BC FLEXSPIB_DATA1_SELECT_INPUT — FLEXSPIB_DATA1_SELECT_INPUT DAISY Register
  [0] DAISY — Selecting Pads Involved in Daisy Chain.
    0=GPIO_SD_B1_02_ALT1 (Selecting Pad: GPIO_SD_B1_02 for Mode: ALT1); 1=GPIO_AD_B1_06_ALT0 (Selecting Pad: GPIO_AD_B1_06 for Mode: ALT0)
0x4C0 FLEXSPIB_DATA2_SELECT_INPUT — FLEXSPIB_DATA2_SELECT_INPUT DAISY Register
  [0] DAISY — Selecting Pads Involved in Daisy Chain.
    0=GPIO_SD_B1_01_ALT1 (Selecting Pad: GPIO_SD_B1_01 for Mode: ALT1); 1=GPIO_AD_B1_05_ALT0 (Selecting Pad: GPIO_AD_B1_05 for Mode: ALT0)
0x4C4 FLEXSPIB_DATA3_SELECT_INPUT — FLEXSPIB_DATA3_SELECT_INPUT DAISY Register
  [0] DAISY — Selecting Pads Involved in Daisy Chain.
    0=GPIO_SD_B1_00_ALT1 (Selecting Pad: GPIO_SD_B1_00 for Mode: ALT1); 1=GPIO_AD_B1_04_ALT0 (Selecting Pad: GPIO_AD_B1_04 for Mode: ALT0)
0x4C8 FLEXSPIA_SCK_SELECT_INPUT — FLEXSPIA_SCK_SELECT_INPUT DAISY Register
  [0] DAISY — Selecting Pads Involved in Daisy Chain.
    0=GPIO_SD_B1_07_ALT1 (Selecting Pad: GPIO_SD_B1_07 for Mode: ALT1); 1=GPIO_AD_B1_14_ALT0 (Selecting Pad: GPIO_AD_B1_14 for Mode: ALT0)
0x4CC LPI2C1_SCL_SELECT_INPUT — LPI2C1_SCL_SELECT_INPUT DAISY Register
  [0] DAISY — Selecting Pads Involved in Daisy Chain.
    0=GPIO_SD_B1_04_ALT2 (Selecting Pad: GPIO_SD_B1_04 for Mode: ALT2); 1=GPIO_AD_B1_00_ALT3 (Selecting Pad: GPIO_AD_B1_00 for Mode: ALT3)
0x4D0 LPI2C1_SDA_SELECT_INPUT — LPI2C1_SDA_SELECT_INPUT DAISY Register
  [0] DAISY — Selecting Pads Involved in Daisy Chain.
    0=GPIO_SD_B1_05_ALT2 (Selecting Pad: GPIO_SD_B1_05 for Mode: ALT2); 1=GPIO_AD_B1_01_ALT3 (Selecting Pad: GPIO_AD_B1_01 for Mode: ALT3)
0x4D4 LPI2C2_SCL_SELECT_INPUT — LPI2C2_SCL_SELECT_INPUT DAISY Register
  [0] DAISY — Selecting Pads Involved in Daisy Chain.
    0=GPIO_SD_B1_11_ALT3 (Selecting Pad: GPIO_SD_B1_11 for Mode: ALT3); 1=GPIO_B0_04_ALT2 (Selecting Pad: GPIO_B0_04 for Mode: ALT2)
0x4D8 LPI2C2_SDA_SELECT_INPUT — LPI2C2_SDA_SELECT_INPUT DAISY Register
  [0] DAISY — Selecting Pads Involved in Daisy Chain.
    0=GPIO_SD_B1_10_ALT3 (Selecting Pad: GPIO_SD_B1_10 for Mode: ALT3); 1=GPIO_B0_05_ALT2 (Selecting Pad: GPIO_B0_05 for Mode: ALT2)
0x4DC LPI2C3_SCL_SELECT_INPUT — LPI2C3_SCL_SELECT_INPUT DAISY Register
  [1:0] DAISY — Selecting Pads Involved in Daisy Chain.
    0=GPIO_EMC_22_ALT2 (Selecting Pad: GPIO_EMC_22 for Mode: ALT2); 1=GPIO_SD_B0_00_ALT2 (Selecting Pad: GPIO_SD_B0_00 for Mode: ALT2); 2=GPIO_AD_B1_07_ALT1 (Selecting Pad: GPIO_AD_B1_07 for Mode: ALT1)
0x4E0 LPI2C3_SDA_SELECT_INPUT — LPI2C3_SDA_SELECT_INPUT DAISY Register
  [1:0] DAISY — Selecting Pads Involved in Daisy Chain.
    0=GPIO_EMC_21_ALT2 (Selecting Pad: GPIO_EMC_21 for Mode: ALT2); 1=GPIO_SD_B0_01_ALT2 (Selecting Pad: GPIO_SD_B0_01 for Mode: ALT2); 2=GPIO_AD_B1_06_ALT1 (Selecting Pad: GPIO_AD_B1_06 for Mode: ALT1)
0x4E4 LPI2C4_SCL_SELECT_INPUT — LPI2C4_SCL_SELECT_INPUT DAISY Register
  [0] DAISY — Selecting Pads Involved in Daisy Chain.
    0=GPIO_EMC_12_ALT2 (Selecting Pad: GPIO_EMC_12 for Mode: ALT2); 1=GPIO_AD_B0_12_ALT0 (Selecting Pad: GPIO_AD_B0_12 for Mode: ALT0)
0x4E8 LPI2C4_SDA_SELECT_INPUT — LPI2C4_SDA_SELECT_INPUT DAISY Register
  [0] DAISY — Selecting Pads Involved in Daisy Chain.
    0=GPIO_EMC_11_ALT2 (Selecting Pad: GPIO_EMC_11 for Mode: ALT2); 1=GPIO_AD_B0_13_ALT0 (Selecting Pad: GPIO_AD_B0_13 for Mode: ALT0)
0x4EC LPSPI1_PCS0_SELECT_INPUT — LPSPI1_PCS0_SELECT_INPUT DAISY Register
  [0] DAISY — Selecting Pads Involved in Daisy Chain.
    0=GPIO_SD_B0_01_ALT4 (Selecting Pad: GPIO_SD_B0_01 for Mode: ALT4); 1=GPIO_EMC_30_ALT3 (Selecting Pad: GPIO_EMC_30 for Mode: ALT3)
0x4F0 LPSPI1_SCK_SELECT_INPUT — LPSPI1_SCK_SELECT_INPUT DAISY Register
  [0] DAISY — Selecting Pads Involved in Daisy Chain.
    0=GPIO_EMC_27_ALT3 (Selecting Pad: GPIO_EMC_27 for Mode: ALT3); 1=GPIO_SD_B0_00_ALT4 (Selecting Pad: GPIO_SD_B0_00 for Mode: ALT4)
